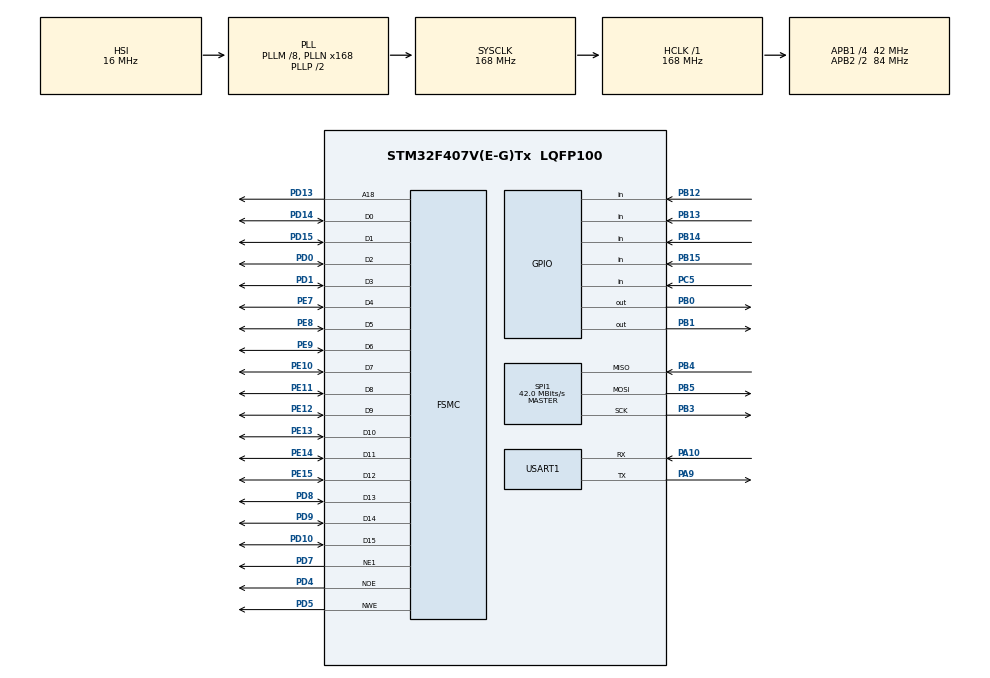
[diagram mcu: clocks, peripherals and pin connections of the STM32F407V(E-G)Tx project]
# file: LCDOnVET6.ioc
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FSMC.AddressSetupTime1=15
FSMC.BusTurnAroundDuration1=0
FSMC.DataSetupTime1=24
FSMC.ExtendedAddressSetupTime1=3
FSMC.ExtendedBusTurnAroundDuration1=0
FSMC.ExtendedDataSetupTime1=2
FSMC.ExtendedMode1=FSMC_EXTENDED_MODE_ENABLE
Mcu.Family=STM32F4
Mcu.Name=STM32F407V(E-G)Tx
Mcu.Package=LQFP100
NVIC.PriorityGroup=NVIC_PRIORITYGROUP_2
NVIC.USART1_IRQn=true\:0\:0\:false\:false\:true\:true\:true
PA10.Mode=Asynchronous
PA10.Signal=USART1_RX
PA13.Mode=Serial_Wire
PA13.Signal=SYS_JTMS-SWDIO
PA14.Mode=Serial_Wire
PA14.Signal=SYS_JTCK-SWCLK
PA9.Mode=Asynchronous
PA9.Signal=USART1_TX
PB0.GPIO_ModeDefaultOutputPP=GPIO_MODE_OUTPUT_PP
PB0.GPIO_PuPd=GPIO_NOPULL
PB0.GPIO_Speed=GPIO_SPEED_FREQ_VERY_HIGH
PB0.PinState=GPIO_PIN_RESET
PB0.Signal=GPIO_Output
PB1.GPIO_ModeDefaultOutputPP=GPIO_MODE_OUTPUT_PP
PB1.GPIO_PuPd=GPIO_NOPULL
PB1.GPIO_Speed=GPIO_SPEED_FREQ_LOW
PB1.PinState=GPIO_PIN_RESET
PB1.Signal=GPIO_Output
PB12.GPIO_PuPd=GPIO_PULLUP
PB12.Signal=GPIO_Input
PB13.GPIO_PuPd=GPIO_PULLUP
PB13.Signal=GPIO_Input
PB14.GPIO_PuPd=GPIO_PULLUP
PB14.Signal=GPIO_Input
PB15.GPIO_PuPd=GPIO_PULLUP
PB15.Signal=GPIO_Input
PB3.Mode=Full_Duplex_Master
PB3.Signal=SPI1_SCK
PB4.Mode=Full_Duplex_Master
PB4.Signal=SPI1_MISO
PB5.Mode=Full_Duplex_Master
PB5.Signal=SPI1_MOSI
PC14-OSC32_IN.Mode=LSE-External-Oscillator
PC14-OSC32_IN.Signal=RCC_OSC32_IN
PC15-OSC32_OUT.Mode=LSE-External-Oscillator
PC15-OSC32_OUT.Signal=RCC_OSC32_OUT
PC5.GPIO_PuPd=GPIO_PULLUP
PC5.Signal=GPIO_Input
PD0.GPIO_Mode=GPIO_MODE_AF_PP
PD0.GPIO_PuPd=GPIO_NOPULL
PD0.GPIO_Speed_High_Default=GPIO_SPEED_FREQ_VERY_HIGH
PD0.Mode=16b-d1
PD0.Signal=FSMC_D2
PD1.GPIO_Mode=GPIO_MODE_AF_PP
PD1.GPIO_PuPd=GPIO_NOPULL
PD1.GPIO_Speed_High_Default=GPIO_SPEED_FREQ_VERY_HIGH
PD1.Mode=16b-d1
PD1.Signal=FSMC_D3
PD10.GPIO_Mode=GPIO_MODE_AF_PP
PD10.GPIO_PuPd=GPIO_NOPULL
PD10.GPIO_Speed_High_Default=GPIO_SPEED_FREQ_VERY_HIGH
PD10.Mode=16b-d1
PD10.Signal=FSMC_D15
PD13.GPIO_Mode=GPIO_MODE_AF_PP
PD13.GPIO_PuPd=GPIO_NOPULL
PD13.GPIO_Speed_High_Default=GPIO_SPEED_FREQ_VERY_HIGH
PD13.Mode=A18_1
PD13.Signal=FSMC_A18
PD14.GPIO_Mode=GPIO_MODE_AF_PP
PD14.GPIO_PuPd=GPIO_NOPULL
PD14.GPIO_Speed_High_Default=GPIO_SPEED_FREQ_VERY_HIGH
PD14.Mode=16b-d1
PD14.Signal=FSMC_D0
PD15.GPIO_Mode=GPIO_MODE_AF_PP
PD15.GPIO_PuPd=GPIO_NOPULL
PD15.GPIO_Speed_High_Default=GPIO_SPEED_FREQ_VERY_HIGH
PD15.Mode=16b-d1
PD15.Signal=FSMC_D1
PD4.GPIO_Mode=GPIO_MODE_AF_PP
PD4.GPIO_PuPd=GPIO_NOPULL
PD4.GPIO_Speed_High_Default=GPIO_SPEED_FREQ_VERY_HIGH
PD4.Mode=Lcd1
PD4.Signal=FSMC_NOE
PD5.GPIO_Mode=GPIO_MODE_AF_PP
PD5.GPIO_PuPd=GPIO_NOPULL
PD5.GPIO_Speed_High_Default=GPIO_SPEED_FREQ_VERY_HIGH
PD5.Mode=Lcd1
PD5.Signal=FSMC_NWE
PD7.GPIO_Mode=GPIO_MODE_AF_PP
PD7.GPIO_PuPd=GPIO_NOPULL
PD7.GPIO_Speed_High_Default=GPIO_SPEED_FREQ_VERY_HIGH
PD7.Mode=NorPsramChipSelect1_1
PD7.Signal=FSMC_NE1
PD8.GPIO_Mode=GPIO_MODE_AF_PP
PD8.GPIO_PuPd=GPIO_NOPULL
PD8.GPIO_Speed_High_Default=GPIO_SPEED_FREQ_VERY_HIGH
PD8.Mode=16b-d1
PD8.Signal=FSMC_D13
PD9.GPIO_Mode=GPIO_MODE_AF_PP
PD9.GPIO_PuPd=GPIO_NOPULL
PD9.GPIO_Speed_High_Default=GPIO_SPEED_FREQ_VERY_HIGH
PD9.Mode=16b-d1
PD9.Signal=FSMC_D14
PE10.GPIO_Mode=GPIO_MODE_AF_PP
PE10.GPIO_PuPd=GPIO_NOPULL
PE10.GPIO_Speed_High_Default=GPIO_SPEED_FREQ_VERY_HIGH
PE10.Mode=16b-d1
PE10.Signal=FSMC_D7
PE11.GPIO_Mode=GPIO_MODE_AF_PP
PE11.GPIO_PuPd=GPIO_NOPULL
PE11.GPIO_Speed_High_Default=GPIO_SPEED_FREQ_VERY_HIGH
PE11.Mode=16b-d1
PE11.Signal=FSMC_D8
PE12.GPIO_Mode=GPIO_MODE_AF_PP
PE12.GPIO_PuPd=GPIO_NOPULL
PE12.GPIO_Speed_High_Default=GPIO_SPEED_FREQ_VERY_HIGH
PE12.Mode=16b-d1
PE12.Signal=FSMC_D9
PE13.GPIO_Mode=GPIO_MODE_AF_PP
PE13.GPIO_PuPd=GPIO_NOPULL
PE13.GPIO_Speed_High_Default=GPIO_SPEED_FREQ_VERY_HIGH
PE13.Mode=16b-d1
PE13.Signal=FSMC_D10
PE14.GPIO_Mode=GPIO_MODE_AF_PP
PE14.GPIO_PuPd=GPIO_NOPULL
PE14.GPIO_Speed_High_Default=GPIO_SPEED_FREQ_VERY_HIGH
PE14.Mode=16b-d1
PE14.Signal=FSMC_D11
PE15.GPIO_Mode=GPIO_MODE_AF_PP
PE15.GPIO_PuPd=GPIO_NOPULL
PE15.GPIO_Speed_High_Default=GPIO_SPEED_FREQ_VERY_HIGH
PE15.Mode=16b-d1
PE15.Signal=FSMC_D12
PE7.GPIO_Mode=GPIO_MODE_AF_PP
PE7.GPIO_PuPd=GPIO_NOPULL
PE7.GPIO_Speed_High_Default=GPIO_SPEED_FREQ_VERY_HIGH
PE7.Mode=16b-d1
PE7.Signal=FSMC_D4
PE8.GPIO_Mode=GPIO_MODE_AF_PP
PE8.GPIO_PuPd=GPIO_NOPULL
PE8.GPIO_Speed_High_Default=GPIO_SPEED_FREQ_VERY_HIGH
PE8.Mode=16b-d1
PE8.Signal=FSMC_D5
PE9.GPIO_Mode=GPIO_MODE_AF_PP
PE9.GPIO_PuPd=GPIO_NOPULL
PE9.GPIO_Speed_High_Default=GPIO_SPEED_FREQ_VERY_HIGH
PE9.Mode=16b-d1
PE9.Signal=FSMC_D6
PH0-OSC_IN.Mode=HSE-External-Oscillator
PH0-OSC_IN.Signal=RCC_OSC_IN
PH1-OSC_OUT.Mode=HSE-External-Oscillator
PH1-OSC_OUT.Signal=RCC_OSC_OUT
ProjectManager.HeapSize=0x200
ProjectManager.StackSize=0x400
ProjectManager.TargetToolchain=MDK-ARM V5
RCC.48MHZClocksFreq_Value=84000000
RCC.AHBFreq_Value=168000000
RCC.APB1CLKDivider=RCC_HCLK_DIV4
RCC.APB1Freq_Value=42000000
RCC.APB1TimFreq_Value=84000000
RCC.APB2CLKDivider=RCC_HCLK_DIV2
RCC.APB2Freq_Value=84000000
RCC.APB2TimFreq_Value=168000000
RCC.CortexFreq_Value=168000000
RCC.HCLKFreq_Value=168000000
RCC.HSE_VALUE=25000000
RCC.HSI_VALUE=16000000
RCC.PLLM=8
RCC.PLLN=168
RCC.SYSCLKFreq_VALUE=168000000
RCC.SYSCLKSource=RCC_SYSCLKSOURCE_PLLCLK
RCC.VCOOutputFreq_Value=336000000
SPI1.BaudRatePrescaler=SPI_BAUDRATEPRESCALER_2
SPI1.CLKPhase=SPI_PHASE_2EDGE
SPI1.CLKPolarity=SPI_POLARITY_HIGH
SPI1.CRCCalculation=SPI_CRCCALCULATION_DISABLE
SPI1.CalculateBaudRate=42.0 MBits/s
SPI1.Direction=SPI_DIRECTION_2LINES
SPI1.Mode=SPI_MODE_MASTER
SPI1.VirtualType=VM_MASTER
USART1.VirtualMode=VM_ASYNC
board=custom

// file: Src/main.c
/* USER CODE BEGIN Header */
/**
  ******************************************************************************
  * @file           : main.c
  * @brief          : Main program body
  ******************************************************************************
  * @attention
  *
  * <h2><center>&copy; Copyright (c) 2019 STMicroelectronics.
  * All rights reserved.</center></h2>
  *
  * This software component is licensed by ST under BSD 3-Clause license,
  * the "License"; You may not use this file except in compliance with the
  * License. You may obtain a copy of the License at:
  *                        opensource.org/licenses/BSD-3-Clause
  *
  ******************************************************************************
  */
/* USER CODE END Header */

#include "main.h"
#include "spi.h"
#include "usart.h"
#include "gpio.h"
#include "fsmc.h"

/* USER CODE BEGIN Includes */
#include "UserMain.h"
#include "ILI93xx.h"
#include "w25qxx.h"
#include "TOUCH/touch.h"
/* USER CODE END Includes */

void SystemClock_Config(void);

int main(void)
{

  /* MCU Configuration--------------------------------------------------------*/

  /* Reset of all peripherals, Initializes the Flash interface and the Systick. */
  HAL_Init();

  /* Configure the system clock */
  SystemClock_Config();

  /* Initialize all configured peripherals */
  MX_GPIO_Init();
  MX_USART1_UART_Init();
  MX_FSMC_Init();
  MX_SPI1_Init();
  /* USER CODE BEGIN 2 */
	TFTLCD_Init();
	//lcddev.id =0x9341;
	//W25QXX_Init();
	//TP_Init();
	//lcddev.id =0x9341;
  /* USER CODE END 2 */

  /* Infinite loop */
  /* USER CODE BEGIN WHILE */

  while (1)
  {
		//LCD_Clear(WHITE);
		POINT_COLOR=RED;
	LCD_ShowString(30,50,200,16,16,"mcudev STM32F4");
	LCD_ShowString(30,70,200,16,16,"SPI TEST");
	LCD_ShowString(30,90,200,16,16,"mcudev.taobao.com");
    /* USER CODE END WHILE */

  }
}

void SystemClock_Config(void)
{
  RCC_OscInitTypeDef RCC_OscInitStruct = {0};
  RCC_ClkInitTypeDef RCC_ClkInitStruct = {0};

  /** Configure the main internal regulator output voltage
  */
  __HAL_RCC_PWR_CLK_ENABLE();
  __HAL_PWR_VOLTAGESCALING_CONFIG(PWR_REGULATOR_VOLTAGE_SCALE1);
  /** Initializes the CPU, AHB and APB busses clocks
  */
  RCC_OscInitStruct.OscillatorType = RCC_OSCILLATORTYPE_HSI;
  RCC_OscInitStruct.HSIState = RCC_HSI_ON;
  RCC_OscInitStruct.HSICalibrationValue = RCC_HSICALIBRATION_DEFAULT;
  RCC_OscInitStruct.PLL.PLLState = RCC_PLL_ON;
  RCC_OscInitStruct.PLL.PLLSource = RCC_PLLSOURCE_HSI;
  RCC_OscInitStruct.PLL.PLLM = 8;
  RCC_OscInitStruct.PLL.PLLN = 168;
  RCC_OscInitStruct.PLL.PLLP = RCC_PLLP_DIV2;
  RCC_OscInitStruct.PLL.PLLQ = 4;
  if (HAL_RCC_OscConfig(&RCC_OscInitStruct) != HAL_OK)
  {
    Error_Handler();
  }
  /** Initializes the CPU, AHB and APB busses clocks
  */
  RCC_ClkInitStruct.ClockType = RCC_CLOCKTYPE_HCLK|RCC_CLOCKTYPE_SYSCLK
                              |RCC_CLOCKTYPE_PCLK1|RCC_CLOCKTYPE_PCLK2;
  RCC_ClkInitStruct.SYSCLKSource = RCC_SYSCLKSOURCE_PLLCLK;
  RCC_ClkInitStruct.AHBCLKDivider = RCC_SYSCLK_DIV1;
  RCC_ClkInitStruct.APB1CLKDivider = RCC_HCLK_DIV4;
  RCC_ClkInitStruct.APB2CLKDivider = RCC_HCLK_DIV2;

  if (HAL_RCC_ClockConfig(&RCC_ClkInitStruct, FLASH_LATENCY_5) != HAL_OK)
  {
    Error_Handler();
  }
}

void Error_Handler(void)
{
}

/************************ (C) COPYRIGHT STMicroelectronics *****END OF FILE****/
